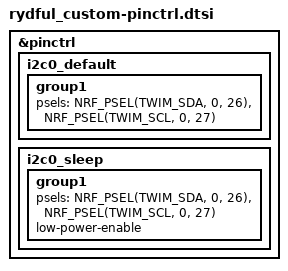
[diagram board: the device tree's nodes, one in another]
/*
 * SPDX-License-Identifier: Apache-2.0
 * Pin control for Rydful Custom PCB
 */

&pinctrl {
	/* I2C0 pins for LIS3DHTR */
	i2c0_default: i2c0_default {
		group1 {
			psels = <NRF_PSEL(TWIM_SDA, 0, 26)>,
			        <NRF_PSEL(TWIM_SCL, 0, 27)>;
		};
	};

	i2c0_sleep: i2c0_sleep {
		group1 {
			psels = <NRF_PSEL(TWIM_SDA, 0, 26)>,
			        <NRF_PSEL(TWIM_SCL, 0, 27)>;
			low-power-enable;
		};
	};
};


